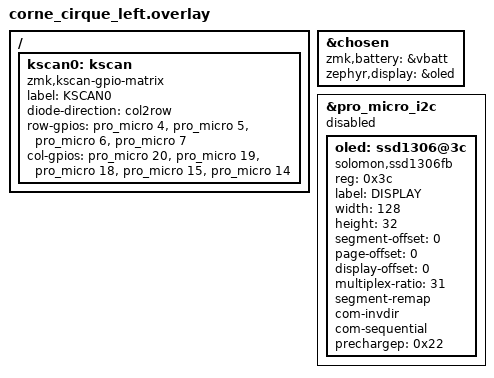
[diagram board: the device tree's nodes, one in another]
/*
 * Copyright (c) 2020 Pete Johanson
 *
 * SPDX-License-Identifier: MIT
 */

#include "corne_cirque.dtsi"

/ {
	kscan0: kscan {
		compatible = "zmk,kscan-gpio-matrix";
		label = "KSCAN0";

		diode-direction = "col2row";
		row-gpios
			= <&pro_micro 4 (GPIO_ACTIVE_HIGH | GPIO_PULL_DOWN)>
			, <&pro_micro 5 (GPIO_ACTIVE_HIGH | GPIO_PULL_DOWN)>
			, <&pro_micro 6 (GPIO_ACTIVE_HIGH | GPIO_PULL_DOWN)>
			, <&pro_micro 7 (GPIO_ACTIVE_HIGH | GPIO_PULL_DOWN)>
			;
		col-gpios
			= <&pro_micro 20 GPIO_ACTIVE_HIGH>
			, <&pro_micro 19 GPIO_ACTIVE_HIGH>
			, <&pro_micro 18 GPIO_ACTIVE_HIGH>
			, <&pro_micro 15 GPIO_ACTIVE_HIGH>
			, <&pro_micro 14 GPIO_ACTIVE_HIGH>
			;
	};
};

&chosen {
	zmk,battery = &vbatt;
	zephyr,display = &oled;
};

&pro_micro_i2c {
	status = "disabled";

	oled: ssd1306@3c {
		compatible = "solomon,ssd1306fb";
		reg = <0x3c>;
		label = "DISPLAY";
		width = <128>;
		height = <32>;
		segment-offset = <0>;
		page-offset = <0>;
		display-offset = <0>;
		multiplex-ratio = <31>;
		segment-remap;
		com-invdir;
		com-sequential;
		prechargep = <0x22>;
	};
};
